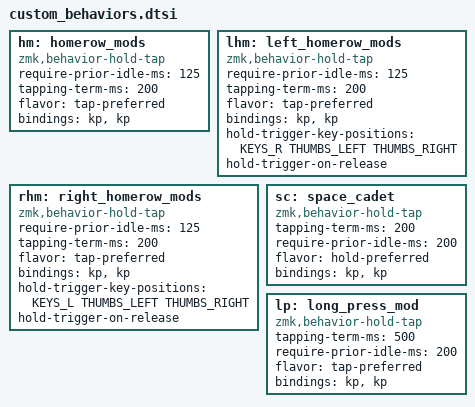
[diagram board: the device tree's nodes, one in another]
hm: homerow_mods {
    compatible = "zmk,behavior-hold-tap";
    #binding-cells = <2>;
    require-prior-idle-ms = <125>;
    tapping-term-ms = <200>;
    flavor = "tap-preferred";
    bindings = <&kp>, <&kp>;
};

lhm: left_homerow_mods {
    compatible = "zmk,behavior-hold-tap";
    #binding-cells = <2>;
    require-prior-idle-ms = <125>;
    tapping-term-ms = <200>;
    flavor = "tap-preferred";
    bindings = <&kp>, <&kp>;
    hold-trigger-key-positions = <KEYS_R THUMBS_LEFT THUMBS_RIGHT>;
    hold-trigger-on-release;  // allow chording, maybe?
};
rhm: right_homerow_mods {
    compatible = "zmk,behavior-hold-tap";
    #binding-cells = <2>;
    require-prior-idle-ms = <125>;
    tapping-term-ms = <200>;
    flavor = "tap-preferred";
    bindings = <&kp>, <&kp>;
    hold-trigger-key-positions = <KEYS_L THUMBS_LEFT THUMBS_RIGHT>;
    hold-trigger-on-release;  // allow chording, maybe?
};

// Deprecated: For QMK-like "Space Cadet" behavior (Shift on hold, parens on tap)
sc: space_cadet {
    compatible = "zmk,behavior-hold-tap";
    #binding-cells = <2>;
    tapping-term-ms = <200>;
    require-prior-idle-ms = <200>;
    flavor = "hold-preferred";
    bindings = <&kp>, <&kp>;
};

// For long-press behavior (e.g. Ctrl-Z on long press of Z, or lock-screen on long press of Macro 4)
lp: long_press_mod {
    compatible = "zmk,behavior-hold-tap";
    #binding-cells = <2>;
    tapping-term-ms = <500>;  // increased to 500ms to avoid accidental activation
    require-prior-idle-ms = <200>;
    flavor = "tap-preferred";
    bindings = <&kp>, <&kp>;
};
